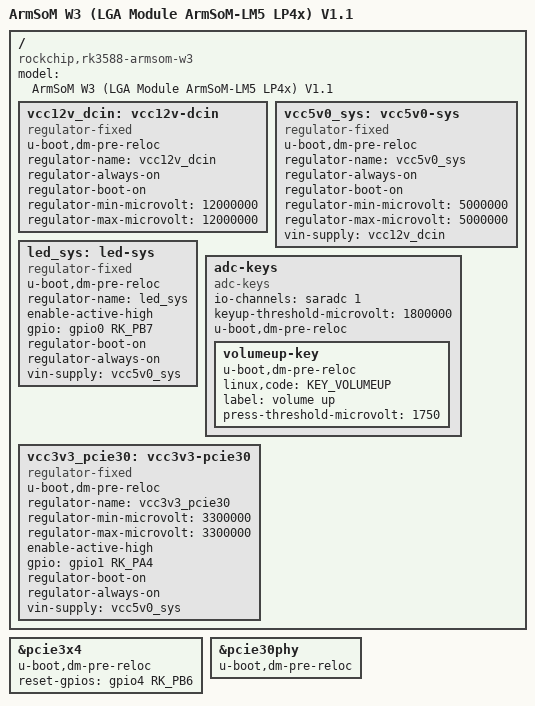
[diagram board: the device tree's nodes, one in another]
// SPDX-License-Identifier: (GPL-2.0+ OR MIT)
/*
 * Copyright (c) 2021 Rockchip Electronics Co., Ltd
 *
 */

/dts-v1/;
#include "rk3588.dtsi"
#include "rk3588-u-boot.dtsi"
#include <dt-bindings/input/input.h>

/ {
	model = "ArmSoM W3 (LGA Module ArmSoM-LM5 LP4x) V1.1";
	compatible = "rockchip,rk3588-armsom-w3", "rockchip,rk3588";

	vcc12v_dcin: vcc12v-dcin {
		u-boot,dm-pre-reloc;
		compatible = "regulator-fixed";
		regulator-name = "vcc12v_dcin";
		regulator-always-on;
		regulator-boot-on;
		regulator-min-microvolt = <12000000>;
		regulator-max-microvolt = <12000000>;
	};

	vcc5v0_sys: vcc5v0-sys {
		u-boot,dm-pre-reloc;
		compatible = "regulator-fixed";
		regulator-name = "vcc5v0_sys";
		regulator-always-on;
		regulator-boot-on;
		regulator-min-microvolt = <5000000>;
		regulator-max-microvolt = <5000000>;
		vin-supply = <&vcc12v_dcin>;
	};

	led_sys: led-sys {
		u-boot,dm-pre-reloc;
		compatible = "regulator-fixed";
		regulator-name = "led_sys";
		enable-active-high;
		gpio = <&gpio0 RK_PB7 GPIO_ACTIVE_HIGH>; // Turn on user led
		regulator-boot-on;
		regulator-always-on;
		vin-supply = <&vcc5v0_sys>;
	};

	adc-keys {
		compatible = "adc-keys";
		io-channels = <&saradc 1>;
		io-channel-names = "buttons";
		keyup-threshold-microvolt = <1800000>;
		u-boot,dm-pre-reloc;
		status = "okay";

		volumeup-key {
			u-boot,dm-pre-reloc;
			linux,code = <KEY_VOLUMEUP>;
			label = "volume up";
			press-threshold-microvolt = <1750>;
		};
	};

	vcc3v3_pcie30: vcc3v3-pcie30 {
		u-boot,dm-pre-reloc;
		compatible = "regulator-fixed";
		regulator-name = "vcc3v3_pcie30";
		regulator-min-microvolt = <3300000>;
		regulator-max-microvolt = <3300000>;
		enable-active-high;
		gpio = <&gpio1 RK_PA4 GPIO_ACTIVE_HIGH>;
		regulator-boot-on;
		regulator-always-on;
		vin-supply = <&vcc5v0_sys>;
	};
};

&pcie3x4 {
	u-boot,dm-pre-reloc;
	reset-gpios = <&gpio4 RK_PB6 GPIO_ACTIVE_HIGH>;
	status = "okay";

};

&pcie30phy {
	u-boot,dm-pre-reloc;
	status = "okay";
};
